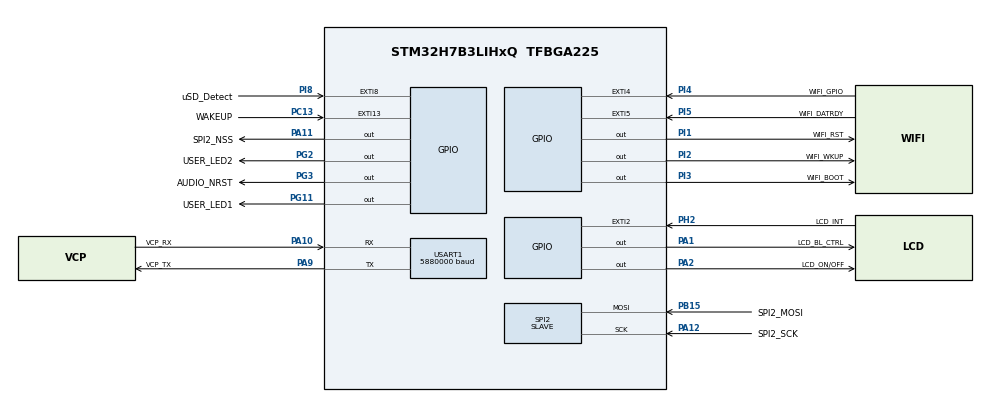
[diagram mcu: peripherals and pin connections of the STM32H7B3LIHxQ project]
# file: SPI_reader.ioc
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Mcu.Family=STM32H7
Mcu.Name=STM32H7B3LIHxQ
Mcu.Package=TFBGA225
NVIC.PriorityGroup=NVIC_PRIORITYGROUP_4
PA0.GPIO_Label=I2S6_WS
PA0.Signal=I2S6_WS
PA1.GPIO_Label=LCD_BL_CTRL
PA1.PinState=GPIO_PIN_SET
PA1.Signal=GPIO_Output
PA10.GPIO_Label=VCP_RX
PA10.Mode=Asynchronous
PA10.Signal=USART1_RX
PA11.GPIO_Label=SPI2_NSS
PA11.Signal=GPIO_Output
PA12.GPIO_Label=SPI2_SCK
PA12.Mode=RX_Only_Simplex_Unidirect_Slave
PA12.Signal=SPI2_SCK
PA13.GPIO_Label=JTMS
PA13.Mode=JTAG_4_pins
PA13.Signal=DEBUG_JTMS-SWDIO
PA14.GPIO_Label=JTCK
PA14.Mode=JTAG_4_pins
PA14.Signal=DEBUG_JTCK-SWCLK
PA15.GPIO_Label=JTDI
PA15.Mode=JTAG_4_pins
PA15.Signal=DEBUG_JTDI
PA2.GPIO_Label=LCD_ON/OFF
PA2.PinState=GPIO_PIN_SET
PA2.Signal=GPIO_Output
PA3.GPIO_Label=I2S6_MCK
PA3.Signal=I2S6_MCK
PA8.GPIO_Label=MCO
PA8.Signal=RCC_MCO_1
PA9.GPIO_Label=VCP_TX
PA9.Mode=Asynchronous
PA9.Signal=USART1_TX
PB14.GPIO_Label=SPI2_MISO
PB14.Signal=SPI2_MISO
PB15.GPIO_Label=SPI2_MOSI
PB15.Mode=RX_Only_Simplex_Unidirect_Slave
PB15.Signal=SPI2_MOSI
PB2.GPIO_Label=OCSPI1_CLK
PB2.Signal=OCTOSPIM_P1_CLK
PB3.GPIO_Label=JTDO_TRACESWO
PB3.Mode=JTAG_4_pins
PB3.Signal=DEBUG_JTDO-SWO
PB4.Signal=DEBUG_JTRST
PC1.GPIO_Label=OCSPI1_IO4
PC1.Signal=OCTOSPIM_P1_IO4
PC10.GPIO_Label=SDIO1_D2
PC10.Signal=SDMMC1_D2
PC11.GPIO_Label=SDIO1_D3
PC11.Signal=SDMMC1_D3
PC12.GPIO_Label=SDIO1_CK
PC12.Signal=SDMMC1_CK
PC13.GPIO_Label=WAKEUP
PC13.Signal=GPXTI13
PC14-OSC32_IN.Mode=LSE-External-Oscillator
PC14-OSC32_IN.Signal=RCC_OSC32_IN
PC15-OSC32_OUT.Mode=LSE-External-Oscillator
PC15-OSC32_OUT.Signal=RCC_OSC32_OUT
PC5.GPIO_Label=OCSPI1_DQS
PC5.Signal=OCTOSPIM_P1_DQS
PC8.GPIO_Label=SDIO1_D0
PC8.Signal=SDMMC1_D0
PC9.GPIO_Label=SDIO1_D1
PC9.Signal=SDMMC1_D1
PD0.GPIO_Label=D2
PD0.Signal=FMC_D2_DA2
PD1.GPIO_Label=D3
PD1.Signal=FMC_D3_DA3
PD10.GPIO_Label=D15
PD10.Signal=FMC_D15_DA15
PD11.GPIO_Label=OCSPI1_IO0
PD11.Signal=OCTOSPIM_P1_IO0
PD12.GPIO_Label=I2C4_SCL
PD12.Signal=I2C4_SCL
PD13.GPIO_Label=I2C4_SDA
PD13.Signal=I2C4_SDA
PD14.GPIO_Label=D0
PD14.Signal=FMC_D0_DA0
PD15.GPIO_Label=D1
PD15.Signal=FMC_D1_DA1
PD2.GPIO_Label=SDIO1_CMD
PD2.Signal=SDMMC1_CMD
PD7.GPIO_Label=OCSPI1_IO7
PD7.Signal=OCTOSPIM_P1_IO7
PD8.GPIO_Label=D13
PD8.Signal=FMC_D13_DA13
PD9.GPIO_Label=D14
PD9.Signal=FMC_D14_DA14
PE0.GPIO_Label=FMC_NBL0
PE0.Signal=FMC_NBL0
PE1.GPIO_Label=FMC_NBL1
PE1.Signal=FMC_NBL1
PE10.GPIO_Label=D7
PE10.Signal=FMC_D7_DA7
PE11.GPIO_Label=D8
PE11.Signal=FMC_D8_DA8
PE12.GPIO_Label=D9
PE12.Signal=FMC_D9_DA9
PE13.GPIO_Label=D10
PE13.Signal=FMC_D10_DA10
PE14.GPIO_Label=D11
PE14.Signal=FMC_D11_DA11
PE15.GPIO_Label=D12
PE15.Signal=FMC_D12_DA12
PE7.GPIO_Label=D4
PE7.Signal=FMC_D4_DA4
PE8.GPIO_Label=D5
PE8.Signal=FMC_D5_DA5
PE9.GPIO_Label=D6
PE9.Signal=FMC_D6_DA6
PF0.GPIO_Label=A0
PF0.Signal=FMC_A0
PF1.GPIO_Label=A1
PF1.Signal=FMC_A1
PF11.GPIO_Label=SDNRAS
PF11.Signal=FMC_SDNRAS
PF12.GPIO_Label=A6
PF12.Signal=FMC_A6
PF13.GPIO_Label=A7
PF13.Signal=FMC_A7
PF14.GPIO_Label=A8
PF14.Signal=FMC_A8
PF15.GPIO_Label=A9
PF15.Signal=FMC_A9
PF2.GPIO_Label=A2
PF2.Signal=FMC_A2
PF3.GPIO_Label=A3
PF3.Signal=FMC_A3
PF4.GPIO_Label=A4
PF4.Signal=FMC_A4
PF5.GPIO_Label=A5
PF5.Signal=FMC_A5
PF6.GPIO_Label=OCSPI1_IO3
PF6.Signal=OCTOSPIM_P1_IO3
PF7.GPIO_Label=OCSPI1_IO2
PF7.Signal=OCTOSPIM_P1_IO2
PF9.GPIO_Label=OCSPI1_IO1
PF9.Signal=OCTOSPIM_P1_IO1
PG0.GPIO_Label=A10
PG0.Signal=FMC_A10
PG1.GPIO_Label=A11
PG1.Signal=FMC_A11
PG11.GPIO_Label=USER_LED1
PG11.Signal=GPIO_Output
PG12.GPIO_Label=I2S6_SDI
PG12.Signal=I2S6_SDI
PG13.GPIO_Label=I2S6_CK
PG13.Signal=I2S6_CK
PG14.GPIO_Label=I2S6_SDO
PG14.Signal=I2S6_SDO
PG15.GPIO_Label=SDNCAS
PG15.Signal=FMC_SDNCAS
PG2.GPIO_Label=USER_LED2
PG2.Signal=GPIO_Output
PG3.GPIO_Label=AUDIO_NRST
PG3.PinState=GPIO_PIN_SET
PG3.Signal=GPIO_Output
PG4.GPIO_Label=A14
PG4.Signal=FMC_A14_BA0
PG5.GPIO_Label=A15
PG5.Signal=FMC_A15_BA1
PG6.GPIO_Label=OCSPI1_NCS
PG6.Signal=OCTOSPIM_P1_NCS
PG8.GPIO_Label=SDCLK
PG8.Signal=FMC_SDCLK
PG9.GPIO_Label=OCSPI1_IO6
PG9.Signal=OCTOSPIM_P1_IO6
PH0-OSC_IN.Mode=HSE-External-Oscillator
PH0-OSC_IN.Signal=RCC_OSC_IN
PH1-OSC_OUT.Mode=HSE-External-Oscillator
PH1-OSC_OUT.Signal=RCC_OSC_OUT
PH2.GPIO_Label=LCD_INT
PH2.Signal=GPXTI2
PH3.GPIO_Label=OCSPI1_IO5
PH3.Signal=OCTOSPIM_P1_IO5
PH5.GPIO_Label=SDNWE
PH5.Signal=FMC_SDNWE
PH6.GPIO_Label=SDNE1
PH6.Signal=FMC_SDNE1
PH7.GPIO_Label=SDCKE1
PH7.Signal=FMC_SDCKE1
PI1.GPIO_Label=WIFI_RST
PI1.Signal=GPIO_Output
PI12.GPIO_Label=LCD_HSYNC
PI12.Signal=LTDC_HSYNC
PI13.GPIO_Label=LCD_VSYNC
PI13.Signal=LTDC_VSYNC
PI14.GPIO_Label=LCD_CLK
PI14.Signal=LTDC_CLK
PI15.GPIO_Label=LCD_R0
PI15.Signal=LTDC_R0
PI2.GPIO_Label=WIFI_WKUP
PI2.Signal=GPIO_Output
PI3.GPIO_Label=WIFI_BOOT
PI3.Signal=GPIO_Output
PI4.GPIO_Label=WIFI_GPIO
PI4.Signal=GPXTI4
PI5.GPIO_Label=WIFI_DATRDY
PI5.Signal=GPXTI5
PI8.GPIO_Label=uSD_Detect
PI8.GPIO_PuPd=GPIO_PULLUP
PI8.Signal=GPXTI8
PJ0.GPIO_Label=LCD_R1
PJ0.Signal=LTDC_R1
PJ1.GPIO_Label=LCD_R2
PJ1.Signal=LTDC_R2
PJ10.GPIO_Label=LCD_G3
PJ10.Signal=LTDC_G3
PJ11.GPIO_Label=LCD_G4
PJ11.Signal=LTDC_G4
PJ12.GPIO_Label=LCD_B0
PJ12.Signal=LTDC_B0
PJ13.GPIO_Label=LCD_B1
PJ13.Signal=LTDC_B1
PJ14.GPIO_Label=LCD_B2
PJ14.Signal=LTDC_B2
PJ15.GPIO_Label=LCD_B3
PJ15.Signal=LTDC_B3
PJ2.GPIO_Label=LCD_R3
PJ2.Signal=LTDC_R3
PJ3.GPIO_Label=LCD_R4
PJ3.Signal=LTDC_R4
PJ4.GPIO_Label=LCD_R5
PJ4.Signal=LTDC_R5
PJ5.GPIO_Label=LCD_R6
PJ5.Signal=LTDC_R6
PJ6.GPIO_Label=LCD_R7
PJ6.Signal=LTDC_R7
PJ7.GPIO_Label=LCD_G0
PJ7.Signal=LTDC_G0
PJ8.GPIO_Label=LCD_G1
PJ8.Signal=LTDC_G1
PJ9.GPIO_Label=LCD_G2
PJ9.Signal=LTDC_G2
PK0.GPIO_Label=LCD_G5
PK0.Signal=LTDC_G5
PK1.GPIO_Label=LCD_G6
PK1.Signal=LTDC_G6
PK2.GPIO_Label=LCD_G7
PK2.Signal=LTDC_G7
PK3.GPIO_Label=LCD_B4
PK3.Signal=LTDC_B4
PK4.GPIO_Label=LCD_B5
PK4.Signal=LTDC_B5
PK5.GPIO_Label=LCD_B6
PK5.Signal=LTDC_B6
PK6.GPIO_Label=LCD_B7
PK6.Signal=LTDC_B7
PK7.GPIO_Label=LCD_DE
PK7.Signal=LTDC_DE
ProjectManager.HeapSize=0x200
ProjectManager.StackSize=0x400
ProjectManager.TargetToolchain=STM32CubeIDE
RCC.ADCFreq_Value=200000000
RCC.APB1Freq_Value=100000000
RCC.APB2Freq_Value=100000000
RCC.APB3Freq_Value=100000000
RCC.APB4Freq_Value=100000000
RCC.CDPPRE=RCC_APB3_DIV2
RCC.CDPPRE1=RCC_APB1_DIV2
RCC.CDPPRE2=RCC_APB2_DIV2
RCC.CortexFreq_Value=200000000
RCC.DIVM1=12
RCC.DIVM2=12
RCC.DIVM3=24
RCC.DIVN1=200
RCC.DIVN2=200
RCC.DIVN3=192
RCC.DIVP3=17
RCC.DIVQ1=3
RCC.DIVR1=4
RCC.DIVR2=4
RCC.FMCCLockSelection=RCC_FMCCLKSOURCE_PLL2
RCC.HCLKFreq_Value=200000000
RCC.HSE_VALUE=24000000
RCC.PLL2FRACN=0
RCC.PLL3FRACN=0
RCC.PLLFRACN=0
RCC.PLLSourceVirtual=RCC_PLLSOURCE_HSE
RCC.PWR_Regulator_Voltage_Scale=PWR_REGULATOR_VOLTAGE_SCALE0
RCC.QSPICLockSelection=RCC_OSPICLKSOURCE_PLL2
RCC.RCC_MCO1Source=RCC_MCO1SOURCE_HSE
RCC.RTCClockSelection=RCC_RTCCLKSOURCE_LSE
RCC.SDMMC1CLockSelection=RCC_SDMMCCLKSOURCE_PLL2
RCC.SPI123CLockSelection=RCC_SPI123CLKSOURCE_CLKP
RCC.SRDPPRE=RCC_APB4_DIV2
RCC.SYSCLKFreq_VALUE=200000000
RCC.SYSCLKSource=RCC_SYSCLKSOURCE_PLLCLK
RCC.SupplySource=PWR_DIRECT_SMPS_SUPPLY
RCC.USBFreq_Value=133333333.33333333
SH.FMC_A0.0=FMC_A0
SH.FMC_A1.0=FMC_A1
SH.FMC_A10.0=FMC_A10
SH.FMC_A11.0=FMC_A11
SH.FMC_A14_BA0.0=FMC_BA0
SH.FMC_A15_BA1.0=FMC_BA1
SH.FMC_A2.0=FMC_A2
SH.FMC_A3.0=FMC_A3
SH.FMC_A4.0=FMC_A4
SH.FMC_A5.0=FMC_A5
SH.FMC_A6.0=FMC_A6
SH.FMC_A7.0=FMC_A7
SH.FMC_A8.0=FMC_A8
SH.FMC_A9.0=FMC_A9
SH.FMC_D0_DA0.0=FMC_D0
SH.FMC_D10_DA10.0=FMC_D10
SH.FMC_D11_DA11.0=FMC_D11
SH.FMC_D12_DA12.0=FMC_D12
SH.FMC_D13_DA13.0=FMC_D13
SH.FMC_D14_DA14.0=FMC_D14
SH.FMC_D15_DA15.0=FMC_D15
SH.FMC_D1_DA1.0=FMC_D1
SH.FMC_D2_DA2.0=FMC_D2
SH.FMC_D3_DA3.0=FMC_D3
SH.FMC_D4_DA4.0=FMC_D4
SH.FMC_D5_DA5.0=FMC_D5
SH.FMC_D6_DA6.0=FMC_D6
SH.FMC_D7_DA7.0=FMC_D7
SH.FMC_D8_DA8.0=FMC_D8
SH.FMC_D9_DA9.0=FMC_D9
SH.FMC_NBL0.0=FMC_NBL0
SH.FMC_NBL1.0=FMC_NBL1
SH.FMC_SDCLK.0=FMC_SDCLK
SH.FMC_SDNCAS.0=FMC_SDNCAS
SH.FMC_SDNRAS.0=FMC_SDNRAS
SH.FMC_SDNWE.0=FMC_SDNWE
SPI2.DataSize=SPI_DATASIZE_8BIT
SPI2.Direction=SPI_DIRECTION_2LINES_RXONLY
SPI2.FifoThreshold=SPI_FIFO_THRESHOLD_01DATA
SPI2.Mode=SPI_MODE_SLAVE
SPI2.VirtualType=VM_SLAVE
USART1.BaudRate=5880000
USART1.VirtualMode-Asynchronous=VM_ASYNC
board=STM32H7B3I-DK

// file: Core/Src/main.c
/* USER CODE BEGIN Header */
/**
  ******************************************************************************
  * @file           : main.c
  * @brief          : Main program body
  ******************************************************************************
  * @attention
  *
  * Copyright (c) 2025 STMicroelectronics.
  * All rights reserved.
  *
  * This software is licensed under terms that can be found in the LICENSE file
  * in the root directory of this software component.
  * If no LICENSE file comes with this software, it is provided AS-IS.
  *
  ******************************************************************************
  */
/* USER CODE END Header */
#include "main.h"

/* USER CODE BEGIN Includes */
#include <stdio.h>
/* USER CODE END Includes */

SPI_HandleTypeDef hspi2;

UART_HandleTypeDef huart1;

void SystemClock_Config(void);
void PeriphCommonClock_Config(void);
static void MX_GPIO_Init(void);
static void MX_SPI2_Init(void);
static void MX_USART1_UART_Init(void);

/* USER CODE BEGIN 0 */
uint8_t data[20];
/* USER CODE END 0 */

int main(void)
{

  /* MCU Configuration--------------------------------------------------------*/

  /* Reset of all peripherals, Initializes the Flash interface and the Systick. */
  HAL_Init();

  /* Configure the system clock */
  SystemClock_Config();

/* Configure the peripherals common clocks */
  PeriphCommonClock_Config();

  /* Initialize all configured peripherals */
  MX_GPIO_Init();
  MX_SPI2_Init();
  MX_USART1_UART_Init();

  /* Infinite loop */
  /* USER CODE BEGIN WHILE */
  //char uart_send_data[10] = "          ";
  char buffer[10] = "          ";
  HAL_StatusTypeDef spi_status;
  while (1)
  {
	 /* while (hspi2.State != HAL_SPI_STATE_READY)
	  {
		  sprintf(buffer, "not ready %d", hspi2.State);
		  HAL_UART_Transmit(&huart1, buffer, 11, 100);
		  HAL_Delay(10);
	  }*/
	  spi_status = HAL_SPI_Receive(&hspi2, &data, 20, 100);
	  if( spi_status != HAL_OK ) {
		  HAL_GPIO_TogglePin(USER_LED1_GPIO_Port, USER_LED1_Pin);
		  char error_message[20] = "\r\nbalabanis";
		  sprintf(error_message, "%d", spi_status);
		  HAL_UART_Transmit(&huart1, &error_message, 11, 100);
	  }
	  else {
		  //sprintf(uart_send_data, "%#X ", data);
		  HAL_UART_Transmit(&huart1, &data, 20, 100); //(&huart1, &uart_send_data, 7, 1000);
	  }

    /* USER CODE END WHILE */

  }
}

void SystemClock_Config(void)
{
  RCC_OscInitTypeDef RCC_OscInitStruct = {0};
  RCC_ClkInitTypeDef RCC_ClkInitStruct = {0};

  /*AXI clock gating */
  RCC->CKGAENR = 0xFFFFFFFF;

  /** Supply configuration update enable
  */
  HAL_PWREx_ConfigSupply(PWR_DIRECT_SMPS_SUPPLY);

  /** Configure the main internal regulator output voltage
  */
  __HAL_PWR_VOLTAGESCALING_CONFIG(PWR_REGULATOR_VOLTAGE_SCALE0);

  while(!__HAL_PWR_GET_FLAG(PWR_FLAG_VOSRDY)) {}

  /** Initializes the RCC Oscillators according to the specified parameters
  * in the RCC_OscInitTypeDef structure.
  */
  RCC_OscInitStruct.OscillatorType = RCC_OSCILLATORTYPE_HSI|RCC_OSCILLATORTYPE_HSE;
  RCC_OscInitStruct.HSEState = RCC_HSE_ON;
  RCC_OscInitStruct.HSIState = RCC_HSI_DIV1;
  RCC_OscInitStruct.HSICalibrationValue = 64;
  RCC_OscInitStruct.PLL.PLLState = RCC_PLL_ON;
  RCC_OscInitStruct.PLL.PLLSource = RCC_PLLSOURCE_HSE;
  RCC_OscInitStruct.PLL.PLLM = 12;
  RCC_OscInitStruct.PLL.PLLN = 200;
  RCC_OscInitStruct.PLL.PLLP = 2;
  RCC_OscInitStruct.PLL.PLLQ = 3;
  RCC_OscInitStruct.PLL.PLLR = 4;
  RCC_OscInitStruct.PLL.PLLRGE = RCC_PLL1VCIRANGE_1;
  RCC_OscInitStruct.PLL.PLLVCOSEL = RCC_PLL1VCOWIDE;
  RCC_OscInitStruct.PLL.PLLFRACN = 0;
  if (HAL_RCC_OscConfig(&RCC_OscInitStruct) != HAL_OK)
  {
    Error_Handler();
  }

  /** Initializes the CPU, AHB and APB buses clocks
  */
  RCC_ClkInitStruct.ClockType = RCC_CLOCKTYPE_HCLK|RCC_CLOCKTYPE_SYSCLK
                              |RCC_CLOCKTYPE_PCLK1|RCC_CLOCKTYPE_PCLK2
                              |RCC_CLOCKTYPE_D3PCLK1|RCC_CLOCKTYPE_D1PCLK1;
  RCC_ClkInitStruct.SYSCLKSource = RCC_SYSCLKSOURCE_PLLCLK;
  RCC_ClkInitStruct.SYSCLKDivider = RCC_SYSCLK_DIV1;
  RCC_ClkInitStruct.AHBCLKDivider = RCC_HCLK_DIV1;
  RCC_ClkInitStruct.APB3CLKDivider = RCC_APB3_DIV2;
  RCC_ClkInitStruct.APB1CLKDivider = RCC_APB1_DIV2;
  RCC_ClkInitStruct.APB2CLKDivider = RCC_APB2_DIV2;
  RCC_ClkInitStruct.APB4CLKDivider = RCC_APB4_DIV2;

  if (HAL_RCC_ClockConfig(&RCC_ClkInitStruct, FLASH_LATENCY_4) != HAL_OK)
  {
    Error_Handler();
  }
}

void PeriphCommonClock_Config(void)
{
  RCC_PeriphCLKInitTypeDef PeriphClkInitStruct = {0};

  /** Initializes the peripherals clock
  */
  PeriphClkInitStruct.PeriphClockSelection = RCC_PERIPHCLK_CKPER;
  PeriphClkInitStruct.CkperClockSelection = RCC_CLKPSOURCE_HSI;
  if (HAL_RCCEx_PeriphCLKConfig(&PeriphClkInitStruct) != HAL_OK)
  {
    Error_Handler();
  }
}

static void MX_SPI2_Init(void)
{

  /* SPI2 parameter configuration*/
  hspi2.Instance = SPI2;
  hspi2.Init.Mode = SPI_MODE_SLAVE;
  hspi2.Init.Direction = SPI_DIRECTION_2LINES_RXONLY;
  hspi2.Init.DataSize = SPI_DATASIZE_8BIT;
  hspi2.Init.CLKPolarity = SPI_POLARITY_LOW;
  hspi2.Init.CLKPhase = SPI_PHASE_1EDGE;
  hspi2.Init.NSS = SPI_NSS_SOFT;
  hspi2.Init.FirstBit = SPI_FIRSTBIT_MSB;
  hspi2.Init.TIMode = SPI_TIMODE_DISABLE;
  hspi2.Init.CRCCalculation = SPI_CRCCALCULATION_DISABLE;
  hspi2.Init.CRCPolynomial = 0x0;
  hspi2.Init.NSSPMode = SPI_NSS_PULSE_DISABLE;
  hspi2.Init.NSSPolarity = SPI_NSS_POLARITY_LOW;
  hspi2.Init.FifoThreshold = SPI_FIFO_THRESHOLD_01DATA;
  hspi2.Init.TxCRCInitializationPattern = SPI_CRC_INITIALIZATION_ALL_ZERO_PATTERN;
  hspi2.Init.RxCRCInitializationPattern = SPI_CRC_INITIALIZATION_ALL_ZERO_PATTERN;
  hspi2.Init.MasterSSIdleness = SPI_MASTER_SS_IDLENESS_00CYCLE;
  hspi2.Init.MasterInterDataIdleness = SPI_MASTER_INTERDATA_IDLENESS_00CYCLE;
  hspi2.Init.MasterReceiverAutoSusp = SPI_MASTER_RX_AUTOSUSP_DISABLE;
  hspi2.Init.MasterKeepIOState = SPI_MASTER_KEEP_IO_STATE_DISABLE;
  hspi2.Init.IOSwap = SPI_IO_SWAP_DISABLE;
  if (HAL_SPI_Init(&hspi2) != HAL_OK)
  {
    Error_Handler();
  }

}

static void MX_USART1_UART_Init(void)
{

  huart1.Instance = USART1;
  huart1.Init.BaudRate = 921600;
  huart1.Init.WordLength = UART_WORDLENGTH_8B;
  huart1.Init.StopBits = UART_STOPBITS_1;
  huart1.Init.Parity = UART_PARITY_NONE;
  huart1.Init.Mode = UART_MODE_TX_RX;
  huart1.Init.HwFlowCtl = UART_HWCONTROL_NONE;
  huart1.Init.OverSampling = UART_OVERSAMPLING_16;
  huart1.Init.OneBitSampling = UART_ONE_BIT_SAMPLE_DISABLE;
  huart1.Init.ClockPrescaler = UART_PRESCALER_DIV1;
  huart1.AdvancedInit.AdvFeatureInit = UART_ADVFEATURE_NO_INIT;
  if (HAL_UART_Init(&huart1) != HAL_OK)
  {
    Error_Handler();
  }
  if (HAL_UARTEx_SetTxFifoThreshold(&huart1, UART_TXFIFO_THRESHOLD_1_8) != HAL_OK)
  {
    Error_Handler();
  }
  if (HAL_UARTEx_SetRxFifoThreshold(&huart1, UART_RXFIFO_THRESHOLD_1_8) != HAL_OK)
  {
    Error_Handler();
  }
  if (HAL_UARTEx_DisableFifoMode(&huart1) != HAL_OK)
  {
    Error_Handler();
  }

}

static void MX_GPIO_Init(void)
{
  GPIO_InitTypeDef GPIO_InitStruct = {0};

  /* GPIO Ports Clock Enable */
  __HAL_RCC_GPIOI_CLK_ENABLE();
  __HAL_RCC_GPIOG_CLK_ENABLE();
  __HAL_RCC_GPIOK_CLK_ENABLE();
  __HAL_RCC_GPIOD_CLK_ENABLE();
  __HAL_RCC_GPIOC_CLK_ENABLE();
  __HAL_RCC_GPIOE_CLK_ENABLE();
  __HAL_RCC_GPIOB_CLK_ENABLE();
  __HAL_RCC_GPIOJ_CLK_ENABLE();
  __HAL_RCC_GPIOA_CLK_ENABLE();
  __HAL_RCC_GPIOF_CLK_ENABLE();
  __HAL_RCC_GPIOH_CLK_ENABLE();

  /*Configure GPIO pin Output Level */
  HAL_GPIO_WritePin(GPIOI, WIFI_BOOT_Pin|WIFI_WKUP_Pin|WIFI_RST_Pin, GPIO_PIN_RESET);

  /*Configure GPIO pin Output Level */
  HAL_GPIO_WritePin(GPIOG, USER_LED1_Pin|USER_LED2_Pin, GPIO_PIN_RESET);

  /*Configure GPIO pin Output Level */
  HAL_GPIO_WritePin(SPI2_NSS_GPIO_Port, SPI2_NSS_Pin, GPIO_PIN_RESET);

  /*Configure GPIO pin Output Level */
  HAL_GPIO_WritePin(AUDIO_NRST_GPIO_Port, AUDIO_NRST_Pin, GPIO_PIN_SET);

  /*Configure GPIO pin Output Level */
  HAL_GPIO_WritePin(GPIOA, LCD_BL_CTRL_Pin|LCD_ON_OFF_Pin, GPIO_PIN_SET);

  /*Configure GPIO pins : WIFI_GPIO_Pin WIFI_DATRDY_Pin */
  GPIO_InitStruct.Pin = WIFI_GPIO_Pin|WIFI_DATRDY_Pin;
  GPIO_InitStruct.Mode = GPIO_MODE_IT_RISING;
  GPIO_InitStruct.Pull = GPIO_NOPULL;
  HAL_GPIO_Init(GPIOI, &GPIO_InitStruct);

  /*Configure GPIO pins : SDNCAS_Pin SDCLK_Pin A15_Pin A14_Pin
                           A11_Pin A10_Pin */
  GPIO_InitStruct.Pin = SDNCAS_Pin|SDCLK_Pin|A15_Pin|A14_Pin
                          |A11_Pin|A10_Pin;
  GPIO_InitStruct.Mode = GPIO_MODE_AF_PP;
  GPIO_InitStruct.Pull = GPIO_NOPULL;
  GPIO_InitStruct.Speed = GPIO_SPEED_FREQ_VERY_HIGH;
  GPIO_InitStruct.Alternate = GPIO_AF12_FMC;
  HAL_GPIO_Init(GPIOG, &GPIO_InitStruct);

  /*Configure GPIO pins : LCD_B6_Pin LCD_B7_Pin LCD_B4_Pin LCD_B5_Pin
                           LCD_DE_Pin LCD_G7_Pin LCD_G6_Pin LCD_G5_Pin */
  GPIO_InitStruct.Pin = LCD_B6_Pin|LCD_B7_Pin|LCD_B4_Pin|LCD_B5_Pin
                          |LCD_DE_Pin|LCD_G7_Pin|LCD_G6_Pin|LCD_G5_Pin;
  GPIO_InitStruct.Mode = GPIO_MODE_AF_PP;
  GPIO_InitStruct.Pull = GPIO_NOPULL;
  GPIO_InitStruct.Speed = GPIO_SPEED_FREQ_LOW;
  GPIO_InitStruct.Alternate = GPIO_AF14_LTDC;
  HAL_GPIO_Init(GPIOK, &GPIO_InitStruct);

  /*Configure GPIO pins : I2S6_SDO_Pin I2S6_SDI_Pin I2S6_CK_Pin */
  GPIO_InitStruct.Pin = I2S6_SDO_Pin|I2S6_SDI_Pin|I2S6_CK_Pin;
  GPIO_InitStruct.Mode = GPIO_MODE_AF_PP;
  GPIO_InitStruct.Pull = GPIO_NOPULL;
  GPIO_InitStruct.Speed = GPIO_SPEED_FREQ_LOW;
  GPIO_InitStruct.Alternate = GPIO_AF5_SPI6;
  HAL_GPIO_Init(GPIOG, &GPIO_InitStruct);

  /*Configure GPIO pin : OCSPI1_IO6_Pin */
  GPIO_InitStruct.Pin = OCSPI1_IO6_Pin;
  GPIO_InitStruct.Mode = GPIO_MODE_AF_PP;
  GPIO_InitStruct.Pull = GPIO_NOPULL;
  GPIO_InitStruct.Speed = GPIO_SPEED_FREQ_VERY_HIGH;
  GPIO_InitStruct.Alternate = GPIO_AF9_OCTOSPIM_P1;
  HAL_GPIO_Init(OCSPI1_IO6_GPIO_Port, &GPIO_InitStruct);

  /*Configure GPIO pin : OCSPI1_IO7_Pin */
  GPIO_InitStruct.Pin = OCSPI1_IO7_Pin;
  GPIO_InitStruct.Mode = GPIO_MODE_AF_PP;
  GPIO_InitStruct.Pull = GPIO_NOPULL;
  GPIO_InitStruct.Speed = GPIO_SPEED_FREQ_VERY_HIGH;
  GPIO_InitStruct.Alternate = GPIO_AF10_OCTOSPIM_P1;
  HAL_GPIO_Init(OCSPI1_IO7_GPIO_Port, &GPIO_InitStruct);

  /*Configure GPIO pins : D3_Pin D2_Pin D0_Pin D1_Pin
                           D13_Pin D15_Pin D14_Pin */
  GPIO_InitStruct.Pin = D3_Pin|D2_Pin|D0_Pin|D1_Pin
                          |D13_Pin|D15_Pin|D14_Pin;
  GPIO_InitStruct.Mode = GPIO_MODE_AF_PP;
  GPIO_InitStruct.Pull = GPIO_NOPULL;
  GPIO_InitStruct.Speed = GPIO_SPEED_FREQ_VERY_HIGH;
  GPIO_InitStruct.Alternate = GPIO_AF12_FMC;
  HAL_GPIO_Init(GPIOD, &GPIO_InitStruct);

  /*Configure GPIO pins : SDIO1_D2_Pin SDIO1_CK_Pin SDIO1_D3_Pin SDIO1_D1_Pin
                           SDIO1_D0_Pin */
  GPIO_InitStruct.Pin = SDIO1_D2_Pin|SDIO1_CK_Pin|SDIO1_D3_Pin|SDIO1_D1_Pin
                          |SDIO1_D0_Pin;
  GPIO_InitStruct.Mode = GPIO_MODE_AF_PP;
  GPIO_InitStruct.Pull = GPIO_NOPULL;
  GPIO_InitStruct.Speed = GPIO_SPEED_FREQ_VERY_HIGH;
  GPIO_InitStruct.Alternate = GPIO_AF12_SDMMC1;
  HAL_GPIO_Init(GPIOC, &GPIO_InitStruct);

  /*Configure GPIO pins : WIFI_BOOT_Pin WIFI_WKUP_Pin WIFI_RST_Pin */
  GPIO_InitStruct.Pin = WIFI_BOOT_Pin|WIFI_WKUP_Pin|WIFI_RST_Pin;
  GPIO_InitStruct.Mode = GPIO_MODE_OUTPUT_PP;
  GPIO_InitStruct.Pull = GPIO_NOPULL;
  GPIO_InitStruct.Speed = GPIO_SPEED_FREQ_LOW;
  HAL_GPIO_Init(GPIOI, &GPIO_InitStruct);

  /*Configure GPIO pins : FMC_NBL0_Pin FMC_NBL1_Pin D9_Pin D4_Pin
                           D10_Pin D11_Pin D7_Pin D6_Pin
                           D12_Pin D5_Pin D8_Pin */
  GPIO_InitStruct.Pin = FMC_NBL0_Pin|FMC_NBL1_Pin|D9_Pin|D4_Pin
                          |D10_Pin|D11_Pin|D7_Pin|D6_Pin
                          |D12_Pin|D5_Pin|D8_Pin;
  GPIO_InitStruct.Mode = GPIO_MODE_AF_PP;
  GPIO_InitStruct.Pull = GPIO_NOPULL;
  GPIO_InitStruct.Speed = GPIO_SPEED_FREQ_VERY_HIGH;
  GPIO_InitStruct.Alternate = GPIO_AF12_FMC;
  HAL_GPIO_Init(GPIOE, &GPIO_InitStruct);

  /*Configure GPIO pins : USER_LED1_Pin AUDIO_NRST_Pin USER_LED2_Pin */
  GPIO_InitStruct.Pin = USER_LED1_Pin|AUDIO_NRST_Pin|USER_LED2_Pin;
  GPIO_InitStruct.Mode = GPIO_MODE_OUTPUT_PP;
  GPIO_InitStruct.Pull = GPIO_NOPULL;
  GPIO_InitStruct.Speed = GPIO_SPEED_FREQ_LOW;
  HAL_GPIO_Init(GPIOG, &GPIO_InitStruct);

  /*Configure GPIO pins : LCD_B3_Pin LCD_B2_Pin LCD_B1_Pin LCD_B0_Pin
                           LCD_G4_Pin LCD_G3_Pin LCD_G2_Pin LCD_G1_Pin
                           LCD_R7_Pin LCD_G0_Pin LCD_R1_Pin LCD_R6_Pin
                           LCD_R2_Pin LCD_R5_Pin LCD_R3_Pin LCD_R4_Pin */
  GPIO_InitStruct.Pin = LCD_B3_Pin|LCD_B2_Pin|LCD_B1_Pin|LCD_B0_Pin
                          |LCD_G4_Pin|LCD_G3_Pin|LCD_G2_Pin|LCD_G1_Pin
                          |LCD_R7_Pin|LCD_G0_Pin|LCD_R1_Pin|LCD_R6_Pin
                          |LCD_R2_Pin|LCD_R5_Pin|LCD_R3_Pin|LCD_R4_Pin;
  GPIO_InitStruct.Mode = GPIO_MODE_AF_PP;
  GPIO_InitStruct.Pull = GPIO_NOPULL;
  GPIO_InitStruct.Speed = GPIO_SPEED_FREQ_LOW;
  GPIO_InitStruct.Alternate = GPIO_AF14_LTDC;
  HAL_GPIO_Init(GPIOJ, &GPIO_InitStruct);

  /*Configure GPIO pin : SDIO1_CMD_Pin */
  GPIO_InitStruct.Pin = SDIO1_CMD_Pin;
  GPIO_InitStruct.Mode = GPIO_MODE_AF_PP;
  GPIO_InitStruct.Pull = GPIO_NOPULL;
  GPIO_InitStruct.Speed = GPIO_SPEED_FREQ_VERY_HIGH;
  GPIO_InitStruct.Alternate = GPIO_AF12_SDMMC1;
  HAL_GPIO_Init(SDIO1_CMD_GPIO_Port, &GPIO_InitStruct);

  /*Configure GPIO pin : uSD_Detect_Pin */
  GPIO_InitStruct.Pin = uSD_Detect_Pin;
  GPIO_InitStruct.Mode = GPIO_MODE_IT_RISING;
  GPIO_InitStruct.Pull = GPIO_PULLUP;
  HAL_GPIO_Init(uSD_Detect_GPIO_Port, &GPIO_InitStruct);

  /*Configure GPIO pins : SPI2_NSS_Pin LCD_BL_CTRL_Pin LCD_ON_OFF_Pin */
  GPIO_InitStruct.Pin = SPI2_NSS_Pin|LCD_BL_CTRL_Pin|LCD_ON_OFF_Pin;
  GPIO_InitStruct.Mode = GPIO_MODE_OUTPUT_PP;
  GPIO_InitStruct.Pull = GPIO_NOPULL;
  GPIO_InitStruct.Speed = GPIO_SPEED_FREQ_LOW;
  HAL_GPIO_Init(GPIOA, &GPIO_InitStruct);

  /*Configure GPIO pin : WAKEUP_Pin */
  GPIO_InitStruct.Pin = WAKEUP_Pin;
  GPIO_InitStruct.Mode = GPIO_MODE_IT_RISING;
  GPIO_InitStruct.Pull = GPIO_NOPULL;
  HAL_GPIO_Init(WAKEUP_GPIO_Port, &GPIO_InitStruct);

  /*Configure GPIO pins : A1_Pin A0_Pin A2_Pin A4_Pin
                           A3_Pin A5_Pin A7_Pin SDNRAS_Pin
                           A9_Pin A8_Pin A6_Pin */
  GPIO_InitStruct.Pin = A1_Pin|A0_Pin|A2_Pin|A4_Pin
                          |A3_Pin|A5_Pin|A7_Pin|SDNRAS_Pin
                          |A9_Pin|A8_Pin|A6_Pin;
  GPIO_InitStruct.Mode = GPIO_MODE_AF_PP;
  GPIO_InitStruct.Pull = GPIO_NOPULL;
  GPIO_InitStruct.Speed = GPIO_SPEED_FREQ_VERY_HIGH;
  GPIO_InitStruct.Alternate = GPIO_AF12_FMC;
  HAL_GPIO_Init(GPIOF, &GPIO_InitStruct);

  /*Configure GPIO pin : MCO_Pin */
  GPIO_InitStruct.Pin = MCO_Pin;
  GPIO_InitStruct.Mode = GPIO_MODE_AF_PP;
  GPIO_InitStruct.Pull = GPIO_NOPULL;
  GPIO_InitStruct.Speed = GPIO_SPEED_FREQ_LOW;
  GPIO_InitStruct.Alternate = GPIO_AF0_MCO;
  HAL_GPIO_Init(MCO_GPIO_Port, &GPIO_InitStruct);

  /*Configure GPIO pin : OCSPI1_NCS_Pin */
  GPIO_InitStruct.Pin = OCSPI1_NCS_Pin;
  GPIO_InitStruct.Mode = GPIO_MODE_AF_PP;
  GPIO_InitStruct.Pull = GPIO_NOPULL;
  GPIO_InitStruct.Speed = GPIO_SPEED_FREQ_VERY_HIGH;
  GPIO_InitStruct.Alternate = GPIO_AF10_OCTOSPIM_P1;
  HAL_GPIO_Init(OCSPI1_NCS_GPIO_Port, &GPIO_InitStruct);

  /*Configure GPIO pins : LCD_HSYNC_Pin LCD_CLK_Pin LCD_VSYNC_Pin LCD_R0_Pin */
  GPIO_InitStruct.Pin = LCD_HSYNC_Pin|LCD_CLK_Pin|LCD_VSYNC_Pin|LCD_R0_Pin;
  GPIO_InitStruct.Mode = GPIO_MODE_AF_PP;
  GPIO_InitStruct.Pull = GPIO_NOPULL;
  GPIO_InitStruct.Speed = GPIO_SPEED_FREQ_LOW;
  GPIO_InitStruct.Alternate = GPIO_AF14_LTDC;
  HAL_GPIO_Init(GPIOI, &GPIO_InitStruct);

  /*Configure GPIO pins : OCSPI1_IO3_Pin OCSPI1_IO2_Pin OCSPI1_IO1_Pin */
  GPIO_InitStruct.Pin = OCSPI1_IO3_Pin|OCSPI1_IO2_Pin|OCSPI1_IO1_Pin;
  GPIO_InitStruct.Mode = GPIO_MODE_AF_PP;
  GPIO_InitStruct.Pull = GPIO_NOPULL;
  GPIO_InitStruct.Speed = GPIO_SPEED_FREQ_VERY_HIGH;
  GPIO_InitStruct.Alternate = GPIO_AF10_OCTOSPIM_P1;
  HAL_GPIO_Init(GPIOF, &GPIO_InitStruct);

  /*Configure GPIO pins : I2C4_SDA_Pin I2C4_SCL_Pin */
  GPIO_InitStruct.Pin = I2C4_SDA_Pin|I2C4_SCL_Pin;
  GPIO_InitStruct.Mode = GPIO_MODE_AF_OD;
  GPIO_InitStruct.Pull = GPIO_NOPULL;
  GPIO_InitStruct.Speed = GPIO_SPEED_FREQ_LOW;
  GPIO_InitStruct.Alternate = GPIO_AF4_I2C4;
  HAL_GPIO_Init(GPIOD, &GPIO_InitStruct);

  /*Configure GPIO pin : OCSPI1_IO0_Pin */
  GPIO_InitStruct.Pin = OCSPI1_IO0_Pin;
  GPIO_InitStruct.Mode = GPIO_MODE_AF_PP;
  GPIO_InitStruct.Pull = GPIO_NOPULL;
  GPIO_InitStruct.Speed = GPIO_SPEED_FREQ_VERY_HIGH;
  GPIO_InitStruct.Alternate = GPIO_AF9_OCTOSPIM_P1;
  HAL_GPIO_Init(OCSPI1_IO0_GPIO_Port, &GPIO_InitStruct);

  /*Configure GPIO pins : OCSPI1_IO4_Pin OCSPI1_DQS_Pin */
  GPIO_InitStruct.Pin = OCSPI1_IO4_Pin|OCSPI1_DQS_Pin;
  GPIO_InitStruct.Mode = GPIO_MODE_AF_PP;
  GPIO_InitStruct.Pull = GPIO_NOPULL;
  GPIO_InitStruct.Speed = GPIO_SPEED_FREQ_VERY_HIGH;
  GPIO_InitStruct.Alternate = GPIO_AF10_OCTOSPIM_P1;
  HAL_GPIO_Init(GPIOC, &GPIO_InitStruct);

  /*Configure GPIO pin : LCD_INT_Pin */
  GPIO_InitStruct.Pin = LCD_INT_Pin;
  GPIO_InitStruct.Mode = GPIO_MODE_IT_RISING;
  GPIO_InitStruct.Pull = GPIO_NOPULL;
  HAL_GPIO_Init(LCD_INT_GPIO_Port, &GPIO_InitStruct);

  /*Configure GPIO pins : SDNE1_Pin SDNWE_Pin SDCKE1_Pin */
  GPIO_InitStruct.Pin = SDNE1_Pin|SDNWE_Pin|SDCKE1_Pin;
  GPIO_InitStruct.Mode = GPIO_MODE_AF_PP;
  GPIO_InitStruct.Pull = GPIO_NOPULL;
  GPIO_InitStruct.Speed = GPIO_SPEED_FREQ_VERY_HIGH;
  GPIO_InitStruct.Alternate = GPIO_AF12_FMC;
  HAL_GPIO_Init(GPIOH, &GPIO_InitStruct);

  /*Configure GPIO pin : OCSPI1_IO5_Pin */
  GPIO_InitStruct.Pin = OCSPI1_IO5_Pin;
  GPIO_InitStruct.Mode = GPIO_MODE_AF_PP;
  GPIO_InitStruct.Pull = GPIO_NOPULL;
  GPIO_InitStruct.Speed = GPIO_SPEED_FREQ_VERY_HIGH;
  GPIO_InitStruct.Alternate = GPIO_AF9_OCTOSPIM_P1;
  HAL_GPIO_Init(OCSPI1_IO5_GPIO_Port, &GPIO_InitStruct);

  /*Configure GPIO pins : I2S6_WS_Pin I2S6_MCK_Pin */
  GPIO_InitStruct.Pin = I2S6_WS_Pin|I2S6_MCK_Pin;
  GPIO_InitStruct.Mode = GPIO_MODE_AF_PP;
  GPIO_InitStruct.Pull = GPIO_NOPULL;
  GPIO_InitStruct.Speed = GPIO_SPEED_FREQ_LOW;
  GPIO_InitStruct.Alternate = GPIO_AF5_SPI6;
  HAL_GPIO_Init(GPIOA, &GPIO_InitStruct);

  /*Configure GPIO pin : OCSPI1_CLK_Pin */
  GPIO_InitStruct.Pin = OCSPI1_CLK_Pin;
  GPIO_InitStruct.Mode = GPIO_MODE_AF_PP;
  GPIO_InitStruct.Pull = GPIO_NOPULL;
  GPIO_InitStruct.Speed = GPIO_SPEED_FREQ_VERY_HIGH;
  GPIO_InitStruct.Alternate = GPIO_AF9_OCTOSPIM_P1;
  HAL_GPIO_Init(OCSPI1_CLK_GPIO_Port, &GPIO_InitStruct);

}

void Error_Handler(void)
{
  __disable_irq();
  while (1)
  {
  }
}
